AUTOSAR XML (schema 00051)
package /FV/Swc
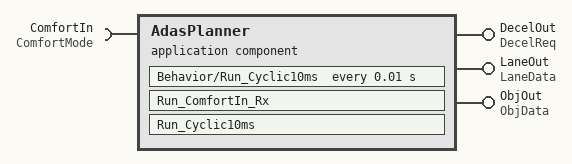
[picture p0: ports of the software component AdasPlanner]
  application sw component type AdasPlanner  # Application software component type AdasPlanner
    require port ComfortIn: required-interface=ComfortMode
    provide port DecelOut: provided-interface=DecelReq
    provide port LaneOut: provided-interface=LaneData
    provide port ObjOut: provided-interface=ObjData
    behavior Behavior
      data received event Dre_ComfortIn: start-on-event=Run_ComfortIn_Rx, data=ComfortIn.mode
      timing event Tev_Cyclic10ms: start-on-event=Behavior/Run_Cyclic10ms, period=0.01
      runnable Run_ComfortIn_Rx
        data-receive-point-by-arguments:
          access Rcv_ComfortIn: accessed-variable=ComfortIn.mode
      runnable Run_Cyclic10ms
        data-send-points:
          access Snd_DecelOut: accessed-variable=DecelOut.decel
          access Snd_LaneOut: accessed-variable=LaneOut.lanes
          access Snd_ObjOut: accessed-variable=ObjOut.objects
  swc implementation AdasPlanner_Impl: programming-language=C, sw-version=1.0.0, behavior=AdasPlanner/Behavior
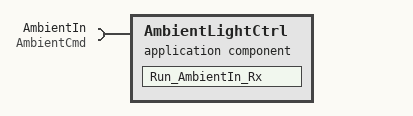
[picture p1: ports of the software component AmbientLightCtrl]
  application sw component type AmbientLightCtrl  # Application software component type AmbientLightCtrl
    require port AmbientIn: required-interface=AmbientCmd
    behavior Behavior
      data received event Dre_AmbientIn: start-on-event=Run_AmbientIn_Rx, data=AmbientIn.color
      runnable Run_AmbientIn_Rx
        data-receive-point-by-arguments:
          access Rcv_AmbientIn: accessed-variable=AmbientIn.color
  swc implementation AmbientLightCtrl_Impl: programming-language=C, sw-version=1.0.0, behavior=AmbientLightCtrl/Behavior
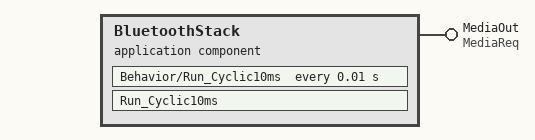
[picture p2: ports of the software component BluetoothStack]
  application sw component type BluetoothStack  # Application software component type BluetoothStack
    provide port MediaOut: provided-interface=MediaReq
    behavior Behavior
      timing event Tev_Cyclic10ms: start-on-event=Behavior/Run_Cyclic10ms, period=0.01
      runnable Run_Cyclic10ms
        data-send-points:
          access Snd_MediaOut: accessed-variable=MediaOut.payload
  swc implementation BluetoothStack_Impl: programming-language=C, sw-version=1.0.0, behavior=BluetoothStack/Behavior
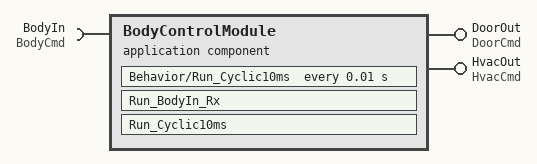
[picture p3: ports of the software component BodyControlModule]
  application sw component type BodyControlModule  # Application software component type BodyControlModule
    require port BodyIn: required-interface=BodyCmd
    provide port DoorOut: provided-interface=DoorCmd
    provide port HvacOut: provided-interface=HvacCmd
    behavior Behavior
      data received event Dre_BodyIn: start-on-event=Run_BodyIn_Rx, data=BodyIn.cmd
      timing event Tev_Cyclic10ms: start-on-event=Behavior/Run_Cyclic10ms, period=0.01
      runnable Run_BodyIn_Rx
        data-receive-point-by-arguments:
          access Rcv_BodyIn: accessed-variable=BodyIn.cmd
      runnable Run_Cyclic10ms
        data-send-points:
          access Snd_DoorOut: accessed-variable=DoorOut.lock
          access Snd_HvacOut: accessed-variable=HvacOut.temp
  swc implementation BodyControlModule_Impl: programming-language=C, sw-version=1.0.0, behavior=BodyControlModule/Behavior
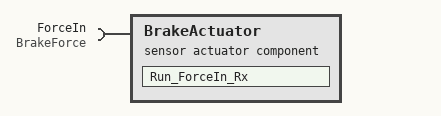
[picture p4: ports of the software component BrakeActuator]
  sensor actuator sw component type BrakeActuator  # Sensor/actuator software component type BrakeActuator
    require port ForceIn: required-interface=BrakeForce
    behavior Behavior
      data received event Dre_ForceIn: start-on-event=Run_ForceIn_Rx, data=ForceIn.force
      runnable Run_ForceIn_Rx
        data-receive-point-by-arguments:
          access Rcv_ForceIn: accessed-variable=ForceIn.force
  swc implementation BrakeActuator_Impl: programming-language=C, sw-version=1.0.0, behavior=BrakeActuator/Behavior
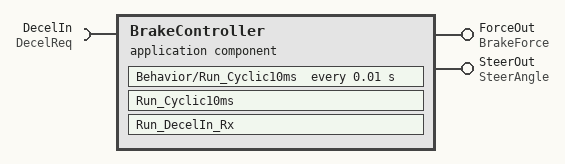
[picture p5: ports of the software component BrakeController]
  application sw component type BrakeController  # Application software component type BrakeController
    require port DecelIn: required-interface=DecelReq
    provide port ForceOut: provided-interface=BrakeForce
    provide port SteerOut: provided-interface=SteerAngle
    behavior Behavior
      data received event Dre_DecelIn: start-on-event=Run_DecelIn_Rx, data=DecelIn.decel
      timing event Tev_Cyclic10ms: start-on-event=Behavior/Run_Cyclic10ms, period=0.01
      runnable Run_Cyclic10ms
        data-send-points:
          access Snd_ForceOut: accessed-variable=ForceOut.force
          access Snd_SteerOut: accessed-variable=SteerOut.angle
      runnable Run_DecelIn_Rx
        data-receive-point-by-arguments:
          access Rcv_DecelIn: accessed-variable=DecelIn.decel
  swc implementation BrakeController_Impl: programming-language=C, sw-version=1.0.0, behavior=BrakeController/Behavior
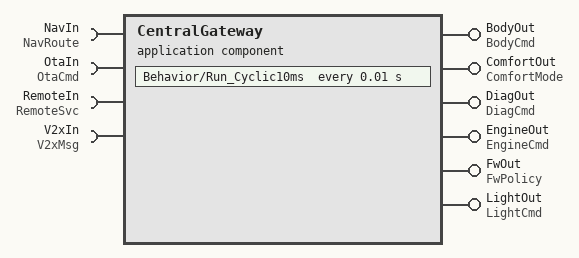
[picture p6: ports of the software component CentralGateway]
  application sw component type CentralGateway  # Application software component type CentralGateway
    6 x provide port:
      BodyOut: provided-interface=BodyCmd
      ComfortOut: provided-interface=ComfortMode
      DiagOut: provided-interface=DiagCmd
      EngineOut: provided-interface=EngineCmd
      FwOut: provided-interface=FwPolicy
      LightOut: provided-interface=LightCmd
    4 x require port:
      NavIn: required-interface=NavRoute
      OtaIn: required-interface=OtaCmd
      RemoteIn: required-interface=RemoteSvc
      V2xIn: required-interface=V2xMsg
    behavior Behavior
      4 x data received event:
        Dre_NavIn: start-on-event=Run_NavIn_Rx, data=NavIn.route
        Dre_OtaIn: start-on-event=Run_OtaIn_Rx, data=OtaIn.pkg
        Dre_RemoteIn: start-on-event=Run_RemoteIn_Rx, data=RemoteIn.val
        Dre_V2xIn: start-on-event=Run_V2xIn_Rx, data=V2xIn.msg
      timing event Tev_Cyclic10ms: start-on-event=Behavior/Run_Cyclic10ms, period=0.01
      5 x runnable:
        Run_Cyclic10ms
          data-send-points:
            6 x access:
              Snd_BodyOut: accessed-variable=BodyOut.cmd
              Snd_ComfortOut: accessed-variable=ComfortOut.mode
              Snd_DiagOut: accessed-variable=DiagOut.cmd
              Snd_EngineOut: accessed-variable=EngineOut.torque
              Snd_FwOut: accessed-variable=FwOut.rule
              Snd_LightOut: accessed-variable=LightOut.level
        Run_NavIn_Rx
          data-receive-point-by-arguments:
            access Rcv_NavIn: accessed-variable=NavIn.route
        Run_OtaIn_Rx
          data-receive-point-by-arguments:
            access Rcv_OtaIn: accessed-variable=OtaIn.pkg
        Run_RemoteIn_Rx
          data-receive-point-by-arguments:
            access Rcv_RemoteIn: accessed-variable=RemoteIn.val
        Run_V2xIn_Rx
          data-receive-point-by-arguments:
            access Rcv_V2xIn: accessed-variable=V2xIn.msg
  swc implementation CentralGateway_Impl: programming-language=C, sw-version=1.0.0, behavior=CentralGateway/Behavior
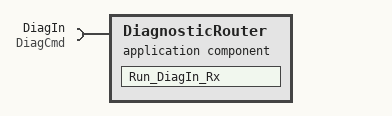
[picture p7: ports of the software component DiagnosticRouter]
  application sw component type DiagnosticRouter  # Application software component type DiagnosticRouter
    require port DiagIn: required-interface=DiagCmd
    behavior Behavior
      data received event Dre_DiagIn: start-on-event=Run_DiagIn_Rx, data=DiagIn.cmd
      runnable Run_DiagIn_Rx
        data-receive-point-by-arguments:
          access Rcv_DiagIn: accessed-variable=DiagIn.cmd
  swc implementation DiagnosticRouter_Impl: programming-language=C, sw-version=1.0.0, behavior=DiagnosticRouter/Behavior
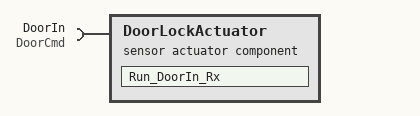
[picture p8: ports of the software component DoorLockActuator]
  sensor actuator sw component type DoorLockActuator  # Sensor/actuator software component type DoorLockActuator
    require port DoorIn: required-interface=DoorCmd
    behavior Behavior
      data received event Dre_DoorIn: start-on-event=Run_DoorIn_Rx, data=DoorIn.lock
      runnable Run_DoorIn_Rx
        data-receive-point-by-arguments:
          access Rcv_DoorIn: accessed-variable=DoorIn.lock
  swc implementation DoorLockActuator_Impl: programming-language=C, sw-version=1.0.0, behavior=DoorLockActuator/Behavior
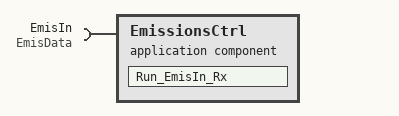
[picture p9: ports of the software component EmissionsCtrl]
  application sw component type EmissionsCtrl  # Application software component type EmissionsCtrl
    require port EmisIn: required-interface=EmisData
    behavior Behavior
      data received event Dre_EmisIn: start-on-event=Run_EmisIn_Rx, data=EmisIn.emis
      runnable Run_EmisIn_Rx
        data-receive-point-by-arguments:
          access Rcv_EmisIn: accessed-variable=EmisIn.emis
  swc implementation EmissionsCtrl_Impl: programming-language=C, sw-version=1.0.0, behavior=EmissionsCtrl/Behavior
  application sw component type EngineController  # Application software component type EngineController
    provide port EmisOut: provided-interface=EmisData
    require port EngIn: required-interface=EngineCmd
    provide port TransOut: provided-interface=TransGear
    behavior Behavior
      data received event Dre_EngIn: start-on-event=Run_EngIn_Rx, data=EngIn.torque
      timing event Tev_Cyclic10ms: start-on-event=Behavior/Run_Cyclic10ms, period=0.01
      runnable Run_Cyclic10ms
        data-send-points:
          access Snd_EmisOut: accessed-variable=EmisOut.emis
          access Snd_TransOut: accessed-variable=TransOut.gear
      runnable Run_EngIn_Rx
        data-receive-point-by-arguments:
          access Rcv_EngIn: accessed-variable=EngIn.torque
  swc implementation EngineController_Impl: programming-language=C, sw-version=1.0.0, behavior=EngineController/Behavior
  application sw component type FirewallManager  # Application software component type FirewallManager
    require port FwIn: required-interface=FwPolicy
    behavior Behavior
      data received event Dre_FwIn: start-on-event=Run_FwIn_Rx, data=FwIn.rule
      runnable Run_FwIn_Rx
        data-receive-point-by-arguments:
          access Rcv_FwIn: accessed-variable=FwIn.rule
  swc implementation FirewallManager_Impl: programming-language=C, sw-version=1.0.0, behavior=FirewallManager/Behavior
  composition sw component type FullVehicle  # Composition FullVehicle
    24 x component:
      adas: type=AdasPlanner
      ambientLight: type=AmbientLightCtrl
      bcm: type=BodyControlModule
      brakeAct: type=BrakeActuator
      brakeCtl: type=BrakeController
      btStack: type=BluetoothStack
      cgw: type=CentralGateway
      diagRouter: type=DiagnosticRouter
      doorLock: type=DoorLockActuator
      emisCtl: type=EmissionsCtrl
      engineCtl: type=EngineController
      firewallMgr: type=FirewallManager
      headlight: type=HeadlightCtrl
      hvacCtl: type=HvacController
      ivi: type=InfotainmentHU
      laneKeep: type=LaneKeepAssist
      mediaPlayer: type=MediaPlayer
      objDetect: type=ObjectDetector
      otaManager: type=OtaManager
      steerCtl: type=SteeringController
      taillight: type=TaillightCtrl
      tcu: type=TelematicsUnit
      transCtl: type=TransmissionCtrl
      v2xStack: type=V2xStack
    connect adas.DecelOut -> brakeCtl.DecelIn
    connect adas.LaneOut -> laneKeep.LaneIn
    connect adas.ObjOut -> objDetect.ObjIn
    connect bcm.DoorOut -> doorLock.DoorIn
    connect bcm.HvacOut -> hvacCtl.HvacIn
    connect brakeCtl.ForceOut -> brakeAct.ForceIn
    connect brakeCtl.SteerOut -> steerCtl.SteerIn
    connect btStack.MediaOut -> ivi.MediaIn
    connect engineCtl.EmisOut -> emisCtl.EmisIn
    connect engineCtl.TransOut -> transCtl.TransIn
    connect cgw.BodyOut -> bcm.BodyIn
    connect cgw.DiagOut -> diagRouter.DiagIn
    connect cgw.EngineOut -> engineCtl.EngIn
    connect cgw.FwOut -> firewallMgr.FwIn
    connect cgw.LightOut -> headlight.LightIn
    connect headlight.AmbientOut -> ambientLight.AmbientIn
    connect headlight.TailOut -> taillight.TailIn
    connect ivi.NavOut -> cgw.NavIn
    connect ivi.StreamOut -> mediaPlayer.StreamIn
    connect otaManager.OtaOut -> cgw.OtaIn
    connect tcu.RemoteOut -> cgw.RemoteIn
    connect v2xStack.V2xOut -> cgw.V2xIn
  application sw component type HeadlightCtrl  # Application software component type HeadlightCtrl
    provide port AmbientOut: provided-interface=AmbientCmd
    require port LightIn: required-interface=LightCmd
    provide port TailOut: provided-interface=TailCmd
    behavior Behavior
      data received event Dre_LightIn: start-on-event=Run_LightIn_Rx, data=LightIn.level
      timing event Tev_Cyclic10ms: start-on-event=Behavior/Run_Cyclic10ms, period=0.01
      runnable Run_Cyclic10ms
        data-send-points:
          access Snd_AmbientOut: accessed-variable=AmbientOut.color
          access Snd_TailOut: accessed-variable=TailOut.level
      runnable Run_LightIn_Rx
        data-receive-point-by-arguments:
          access Rcv_LightIn: accessed-variable=LightIn.level
  swc implementation HeadlightCtrl_Impl: programming-language=C, sw-version=1.0.0, behavior=HeadlightCtrl/Behavior
  application sw component type HvacController  # Application software component type HvacController
    require port HvacIn: required-interface=HvacCmd
    behavior Behavior
      data received event Dre_HvacIn: start-on-event=Run_HvacIn_Rx, data=HvacIn.temp
      runnable Run_HvacIn_Rx
        data-receive-point-by-arguments:
          access Rcv_HvacIn: accessed-variable=HvacIn.temp
  swc implementation HvacController_Impl: programming-language=C, sw-version=1.0.0, behavior=HvacController/Behavior
  application sw component type InfotainmentHU  # Application software component type InfotainmentHU
    require port MediaIn: required-interface=MediaReq
    provide port NavOut: provided-interface=NavRoute
    provide port StreamOut: provided-interface=MediaStream
    behavior Behavior
      data received event Dre_MediaIn: start-on-event=Run_MediaIn_Rx, data=MediaIn.payload
      timing event Tev_Cyclic10ms: start-on-event=Behavior/Run_Cyclic10ms, period=0.01
      runnable Run_Cyclic10ms
        data-send-points:
          access Snd_NavOut: accessed-variable=NavOut.route
          access Snd_StreamOut: accessed-variable=StreamOut.stream
      runnable Run_MediaIn_Rx
        data-receive-point-by-arguments:
          access Rcv_MediaIn: accessed-variable=MediaIn.payload
  swc implementation InfotainmentHU_Impl: programming-language=C, sw-version=1.0.0, behavior=InfotainmentHU/Behavior
  application sw component type LaneKeepAssist  # Application software component type LaneKeepAssist
    require port LaneIn: required-interface=LaneData
    behavior Behavior
      data received event Dre_LaneIn: start-on-event=Run_LaneIn_Rx, data=LaneIn.lanes
      runnable Run_LaneIn_Rx
        data-receive-point-by-arguments:
          access Rcv_LaneIn: accessed-variable=LaneIn.lanes
  swc implementation LaneKeepAssist_Impl: programming-language=C, sw-version=1.0.0, behavior=LaneKeepAssist/Behavior
  application sw component type MediaPlayer  # Application software component type MediaPlayer
    require port StreamIn: required-interface=MediaStream
    behavior Behavior
      data received event Dre_StreamIn: start-on-event=Run_StreamIn_Rx, data=StreamIn.stream
      runnable Run_StreamIn_Rx
        data-receive-point-by-arguments:
          access Rcv_StreamIn: accessed-variable=StreamIn.stream
  swc implementation MediaPlayer_Impl: programming-language=C, sw-version=1.0.0, behavior=MediaPlayer/Behavior
  application sw component type ObjectDetector  # Application software component type ObjectDetector
    require port ObjIn: required-interface=ObjData
    behavior Behavior
      data received event Dre_ObjIn: start-on-event=Run_ObjIn_Rx, data=ObjIn.objects
      runnable Run_ObjIn_Rx
        data-receive-point-by-arguments:
          access Rcv_ObjIn: accessed-variable=ObjIn.objects
  swc implementation ObjectDetector_Impl: programming-language=C, sw-version=1.0.0, behavior=ObjectDetector/Behavior
  application sw component type OtaManager  # Application software component type OtaManager
    provide port OtaOut: provided-interface=OtaCmd
    behavior Behavior
      timing event Tev_Cyclic10ms: start-on-event=Behavior/Run_Cyclic10ms, period=0.01
      runnable Run_Cyclic10ms
        data-send-points:
          access Snd_OtaOut: accessed-variable=OtaOut.pkg
  swc implementation OtaManager_Impl: programming-language=C, sw-version=1.0.0, behavior=OtaManager/Behavior
  sensor actuator sw component type SteeringController  # Sensor/actuator software component type SteeringController
    require port SteerIn: required-interface=SteerAngle
    behavior Behavior
      data received event Dre_SteerIn: start-on-event=Run_SteerIn_Rx, data=SteerIn.angle
      runnable Run_SteerIn_Rx
        data-receive-point-by-arguments:
          access Rcv_SteerIn: accessed-variable=SteerIn.angle
  swc implementation SteeringController_Impl: programming-language=C, sw-version=1.0.0, behavior=SteeringController/Behavior
  sensor actuator sw component type TaillightCtrl  # Sensor/actuator software component type TaillightCtrl
    require port TailIn: required-interface=TailCmd
    behavior Behavior
      data received event Dre_TailIn: start-on-event=Run_TailIn_Rx, data=TailIn.level
      runnable Run_TailIn_Rx
        data-receive-point-by-arguments:
          access Rcv_TailIn: accessed-variable=TailIn.level
  swc implementation TaillightCtrl_Impl: programming-language=C, sw-version=1.0.0, behavior=TaillightCtrl/Behavior
  application sw component type TelematicsUnit  # Application software component type TelematicsUnit
    provide port RemoteOut: provided-interface=RemoteSvc
    behavior Behavior
      timing event Tev_Cyclic10ms: start-on-event=Behavior/Run_Cyclic10ms, period=0.01
      runnable Run_Cyclic10ms
        data-send-points:
          access Snd_RemoteOut: accessed-variable=RemoteOut.val
  swc implementation TelematicsUnit_Impl: programming-language=C, sw-version=1.0.0, behavior=TelematicsUnit/Behavior
  application sw component type TransmissionCtrl  # Application software component type TransmissionCtrl
    require port TransIn: required-interface=TransGear
    behavior Behavior
      data received event Dre_TransIn: start-on-event=Run_TransIn_Rx, data=TransIn.gear
      runnable Run_TransIn_Rx
        data-receive-point-by-arguments:
          access Rcv_TransIn: accessed-variable=TransIn.gear
  swc implementation TransmissionCtrl_Impl: programming-language=C, sw-version=1.0.0, behavior=TransmissionCtrl/Behavior
  application sw component type V2xStack  # Application software component type V2xStack
    provide port V2xOut: provided-interface=V2xMsg
    behavior Behavior
      timing event Tev_Cyclic10ms: start-on-event=Behavior/Run_Cyclic10ms, period=0.01
      runnable Run_Cyclic10ms
        data-send-points:
          access Snd_V2xOut: accessed-variable=V2xOut.msg
  swc implementation V2xStack_Impl: programming-language=C, sw-version=1.0.0, behavior=V2xStack/Behavior
